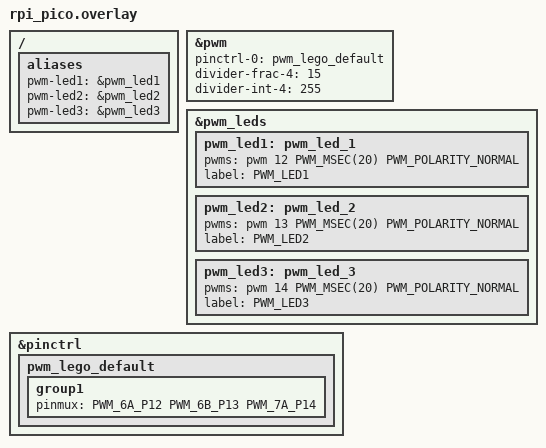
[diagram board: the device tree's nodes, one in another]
&pwm {
	pinctrl-0 = <&pwm_lego_default>;
	pinctrl-names = "default";
	status = "okay";
	divider-frac-4 = <15>;
	divider-int-4 = <255>;
};

&pwm_leds {
	pwm_led1: pwm_led_1 {
		pwms = <&pwm 12 PWM_MSEC(20) PWM_POLARITY_NORMAL>;
		label = "PWM_LED1";
		status = "okay";
	};
	pwm_led2: pwm_led_2 {
		pwms = <&pwm 13 PWM_MSEC(20) PWM_POLARITY_NORMAL>;
		label = "PWM_LED2";
		status = "okay";
	};
	pwm_led3: pwm_led_3 {
		pwms = <&pwm 14 PWM_MSEC(20) PWM_POLARITY_NORMAL>;
		label = "PWM_LED3";
		status = "okay";
	};
};

&pinctrl {
	pwm_lego_default: pwm_lego_default {
		group1 {
			pinmux = <PWM_6A_P12 PWM_6B_P13 PWM_7A_P14>;
		};
	};
};

/{
	aliases {
		pwm-led1 = &pwm_led1;
		pwm-led2 = &pwm_led2;
		pwm-led3 = &pwm_led3;
	};
};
